# TM4C129ENCPDT register map
File version: 1.0
CPU: CORTEX_M4 1.0, other endian, MPU, FPU, 3 interrupt priority bits
Registers are 32-bit, read-write, reset 0x0 unless marked. A register's access mark holds for its fields unless they carry their own. Offsets are from the block's base; [hi:lo] are bit positions; lines under a group give offsets from that group; {n}, {i} and the like mark numbered series.

## NVIC — NVIC register addresses
Base 0xE000E000
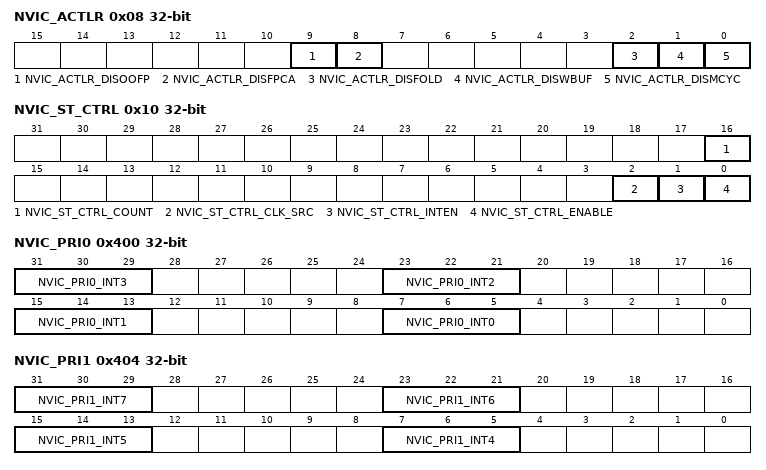
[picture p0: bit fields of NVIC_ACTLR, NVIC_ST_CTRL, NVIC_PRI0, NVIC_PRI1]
0x08 NVIC_ACTLR — Auxiliary Control
  [9] NVIC_ACTLR_DISOOFP — [9:9] Disable Out-Of-Order Floating Point
  [8] NVIC_ACTLR_DISFPCA — [8:8] Disable CONTROL
  [2] NVIC_ACTLR_DISFOLD — [2:2] Disable IT Folding
  [1] NVIC_ACTLR_DISWBUF — [1:1] Disable Write Buffer
  [0] NVIC_ACTLR_DISMCYC — [0:0] Disable Interrupts of Multiple Cycle Instructions
0x10 NVIC_ST_CTRL — SysTick Control and Status Register
  [16] NVIC_ST_CTRL_COUNT — [16:16] Count Flag
  [2] NVIC_ST_CTRL_CLK_SRC — [2:2] Clock Source
  [1] NVIC_ST_CTRL_INTEN — [1:1] Interrupt Enable
  [0] NVIC_ST_CTRL_ENABLE — [0:0] Enable
0x14 NVIC_ST_RELOAD — SysTick Reload Value Register
  [23:0] NVIC_ST_RELOAD — [23:0] Reload Value
0x18 NVIC_ST_CURRENT — SysTick Current Value Register
  [23:0] NVIC_ST_CURRENT — [23:0] Current Value
{0x100+4i} NVIC_EN{i} (i=0..3) — Interrupt {32i}-{32i+31} Set Enable
  [31:0] NVIC_EN{i}_INT — [31:0] Interrupt Enable
{0x180+4i} NVIC_DIS{i} (i=0..3) — Interrupt {32i}-{32i+31} Clear Enable
  [31:0] NVIC_DIS{i}_INT — [31:0] Interrupt Disable
{0x200+4i} NVIC_PEND{i} (i=0..3) — Interrupt {32i}-{32i+31} Set Pending
  [31:0] NVIC_PEND{i}_INT — [31:0] Interrupt Set Pending
{0x280+4i} NVIC_UNPEND{i} (i=0..3) — Interrupt {32i}-{32i+31} Clear Pending
  [31:0] NVIC_UNPEND{i}_INT — [31:0] Interrupt Clear Pending
{0x300+4i} NVIC_ACTIVE{i} (i=0..3) — Interrupt {32i}-{32i+31} Active Bit
  [31:0] NVIC_ACTIVE{i}_INT — [31:0] Interrupt Active
0x400 NVIC_PRI0 — Interrupt 0-3 Priority
  [8n+7:8n+5] NVIC_PRI0_INT{n} (n=0..3) — [{8n+7}:{8n+5}] Interrupt {n} Priority Mask
0x404 NVIC_PRI1 — Interrupt 4-7 Priority
  [8n-25:8n-27] NVIC_PRI1_INT{n} (n=4..7) — [{8n-25}:{8n-27}] Interrupt {n} Priority Mask
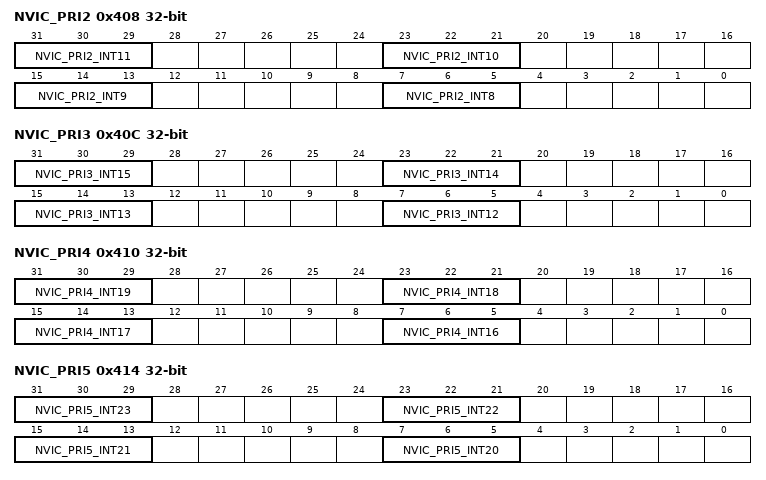
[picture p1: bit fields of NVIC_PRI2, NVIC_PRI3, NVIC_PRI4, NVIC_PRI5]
0x408 NVIC_PRI2 — Interrupt 8-11 Priority
  [8n-57:8n-59] NVIC_PRI2_INT{n} (n=8..11) — [{8n-57}:{8n-59}] Interrupt {n} Priority Mask
0x40C NVIC_PRI3 — Interrupt 12-15 Priority
  [8n-89:8n-91] NVIC_PRI3_INT{n} (n=12..15) — [{8n-89}:{8n-91}] Interrupt {n} Priority Mask
0x410 NVIC_PRI4 — Interrupt 16-19 Priority
  [8n-121:8n-123] NVIC_PRI4_INT{n} (n=16..19) — [{8n-121}:{8n-123}] Interrupt {n} Priority Mask
0x414 NVIC_PRI5 — Interrupt 20-23 Priority
  [8n-153:8n-155] NVIC_PRI5_INT{n} (n=20..23) — [{8n-153}:{8n-155}] Interrupt {n} Priority Mask
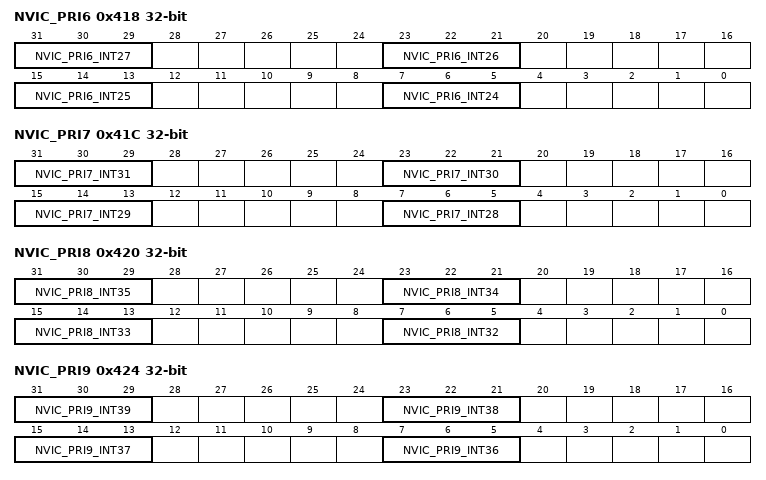
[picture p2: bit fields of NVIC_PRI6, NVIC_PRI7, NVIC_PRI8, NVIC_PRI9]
0x418 NVIC_PRI6 — Interrupt 24-27 Priority
  [8n-185:8n-187] NVIC_PRI6_INT{n} (n=24..27) — [{8n-185}:{8n-187}] Interrupt {n} Priority Mask
0x41C NVIC_PRI7 — Interrupt 28-31 Priority
  [8n-217:8n-219] NVIC_PRI7_INT{n} (n=28..31) — [{8n-217}:{8n-219}] Interrupt {n} Priority Mask
0x420 NVIC_PRI8 — Interrupt 32-35 Priority
  [8n-249:8n-251] NVIC_PRI8_INT{n} (n=32..35) — [{8n-249}:{8n-251}] Interrupt {n} Priority Mask
0x424 NVIC_PRI9 — Interrupt 36-39 Priority
  [8n-281:8n-283] NVIC_PRI9_INT{n} (n=36..39) — [{8n-281}:{8n-283}] Interrupt {n} Priority Mask
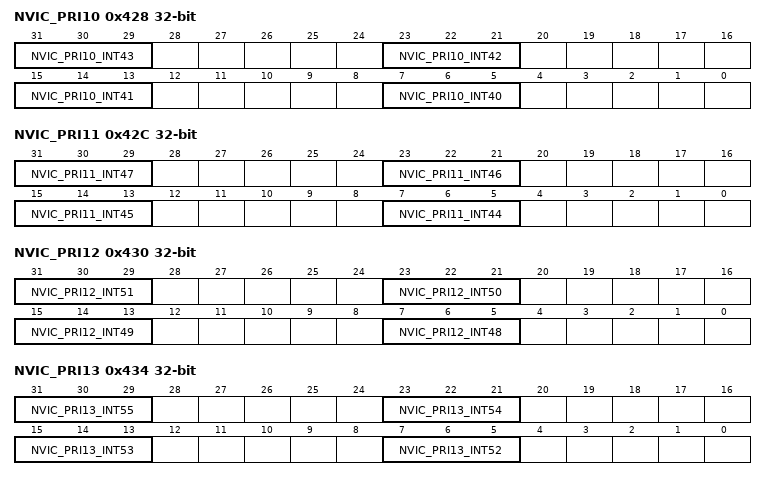
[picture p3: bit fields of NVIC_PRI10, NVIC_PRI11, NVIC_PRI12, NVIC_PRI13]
0x428 NVIC_PRI10 — Interrupt 40-43 Priority
  [8n-313:8n-315] NVIC_PRI10_INT{n} (n=40..43) — [{8n-313}:{8n-315}] Interrupt {n} Priority Mask
0x42C NVIC_PRI11 — Interrupt 44-47 Priority
  [8n-345:8n-347] NVIC_PRI11_INT{n} (n=44..47) — [{8n-345}:{8n-347}] Interrupt {n} Priority Mask
0x430 NVIC_PRI12 — Interrupt 48-51 Priority
  [8n-377:8n-379] NVIC_PRI12_INT{n} (n=48..51) — [{8n-377}:{8n-379}] Interrupt {n} Priority Mask
0x434 NVIC_PRI13 — Interrupt 52-55 Priority
  [8n-409:8n-411] NVIC_PRI13_INT{n} (n=52..55) — [{8n-409}:{8n-411}] Interrupt {n} Priority Mask
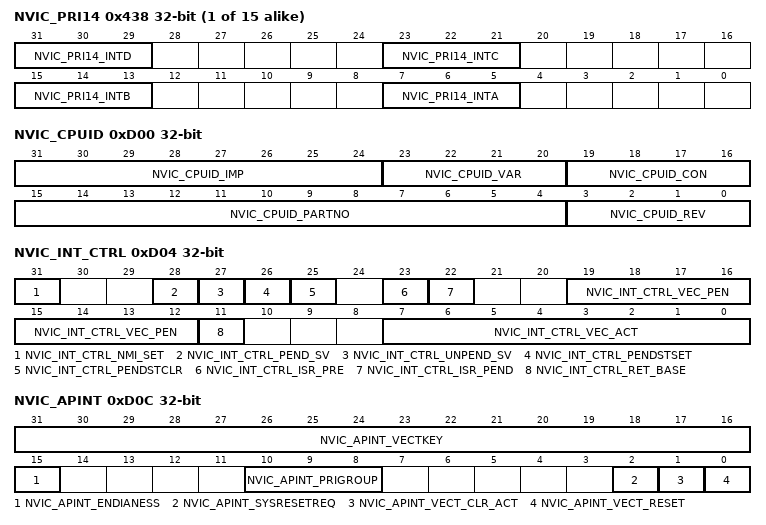
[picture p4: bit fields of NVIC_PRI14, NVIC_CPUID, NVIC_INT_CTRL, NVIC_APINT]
{0x400+4i} NVIC_PRI{i} (i=14..28) — Interrupt {4i}-{4i+3} Priority
  [31:29] NVIC_PRI{i}_INTD — [31:29] Interrupt {4i+3} Priority Mask
  [23:21] NVIC_PRI{i}_INTC — [23:21] Interrupt {4i+2} Priority Mask
  [15:13] NVIC_PRI{i}_INTB — [15:13] Interrupt {4i+1} Priority Mask
  [7:5] NVIC_PRI{i}_INTA — [7:5] Interrupt {4i} Priority Mask
0xD00 NVIC_CPUID — CPU ID Base
  [31:24] NVIC_CPUID_IMP — [31:24] Implementer Code
    0x41000000=NVIC_CPUID_IMP_ARM (ARM)
  [23:20] NVIC_CPUID_VAR — [23:20] Variant Number
  [19:16] NVIC_CPUID_CON — [19:16] Constant
  [15:4] NVIC_CPUID_PARTNO — [15:4] Part Number
    0xC240=NVIC_CPUID_PARTNO_CM4 (Cortex-M4 processor)
  [3:0] NVIC_CPUID_REV — [3:0] Revision Number
0xD04 NVIC_INT_CTRL — Interrupt Control and State
  [31] NVIC_INT_CTRL_NMI_SET — [31:31] NMI Set Pending
  [28] NVIC_INT_CTRL_PEND_SV — [28:28] PendSV Set Pending
  [27] NVIC_INT_CTRL_UNPEND_SV — [27:27] PendSV Clear Pending
  [26] NVIC_INT_CTRL_PENDSTSET — [26:26] SysTick Set Pending
  [25] NVIC_INT_CTRL_PENDSTCLR — [25:25] SysTick Clear Pending
  [23] NVIC_INT_CTRL_ISR_PRE — [23:23] Debug Interrupt Handling
  [22] NVIC_INT_CTRL_ISR_PEND — [22:22] Interrupt Pending
  [19:12] NVIC_INT_CTRL_VEC_PEN — [19:12] Interrupt Pending Vector Number
    0x2000=NVIC_INT_CTRL_VEC_PEN_NMI (NMI); 0x3000=NVIC_INT_CTRL_VEC_PEN_HARD (Hard fault); 0x4000=NVIC_INT_CTRL_VEC_PEN_MEM (Memory management fault); 0x5000=NVIC_INT_CTRL_VEC_PEN_BUS (Bus fault); 0x6000=NVIC_INT_CTRL_VEC_PEN_USG (Usage fault); 0xB000=NVIC_INT_CTRL_VEC_PEN_SVC (SVCall); 0xE000=NVIC_INT_CTRL_VEC_PEN_PNDSV (PendSV); 0xF000=NVIC_INT_CTRL_VEC_PEN_TICK (SysTick)
  [11] NVIC_INT_CTRL_RET_BASE — [11:11] Return to Base
  [7:0] NVIC_INT_CTRL_VEC_ACT — [7:0] Interrupt Pending Vector Number
0xD08 NVIC_VTABLE — Vector Table Offset
  [31:10] NVIC_VTABLE_OFFSET — [31:10] Vector Table Offset
0xD0C NVIC_APINT — Application Interrupt and Reset Control
  [31:16] NVIC_APINT_VECTKEY — [31:16] Register Key
    0x5FA0000=NVIC_APINT_VECTKEY (Vector key)
  [15] NVIC_APINT_ENDIANESS — [15:15] Data Endianess
  [10:8] NVIC_APINT_PRIGROUP — [10:8] Interrupt Priority Grouping
    0=NVIC_APINT_PRIGROUP_7_1 (Priority group 7.1 split); 0x100=NVIC_APINT_PRIGROUP_6_2 (Priority group 6.2 split); 0x200=NVIC_APINT_PRIGROUP_5_3 (Priority group 5.3 split); 0x300=NVIC_APINT_PRIGROUP_4_4 (Priority group 4.4 split); 0x400=NVIC_APINT_PRIGROUP_3_5 (Priority group 3.5 split); 0x500=NVIC_APINT_PRIGROUP_2_6 (Priority group 2.6 split); 0x600=NVIC_APINT_PRIGROUP_1_7 (Priority group 1.7 split); 0x700=NVIC_APINT_PRIGROUP_0_8 (Priority group 0.8 split)
  [2] NVIC_APINT_SYSRESETREQ — [2:2] System Reset Request
  [1] NVIC_APINT_VECT_CLR_ACT — [1:1] Clear Active NMI / Fault
  [0] NVIC_APINT_VECT_RESET — [0:0] System Reset
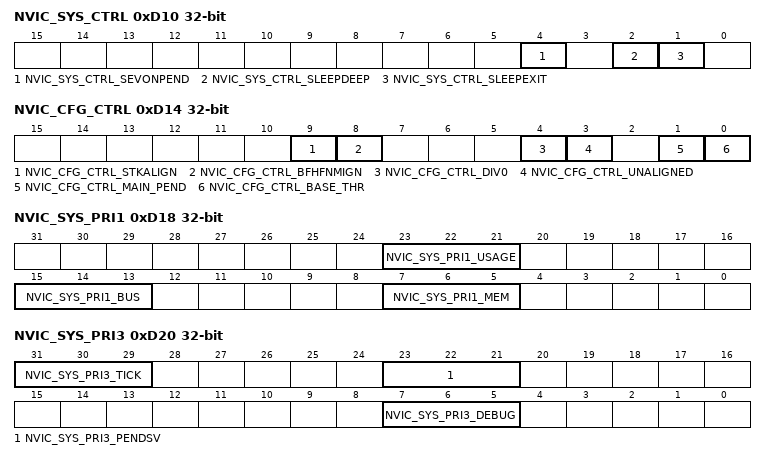
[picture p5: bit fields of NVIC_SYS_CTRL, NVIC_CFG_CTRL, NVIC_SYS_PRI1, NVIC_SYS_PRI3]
0xD10 NVIC_SYS_CTRL — System Control
  [4] NVIC_SYS_CTRL_SEVONPEND — [4:4] Wake Up on Pending
  [2] NVIC_SYS_CTRL_SLEEPDEEP — [2:2] Deep Sleep Enable
  [1] NVIC_SYS_CTRL_SLEEPEXIT — [1:1] Sleep on ISR Exit
0xD14 NVIC_CFG_CTRL — Configuration and Control
  [9] NVIC_CFG_CTRL_STKALIGN — [9:9] Stack Alignment on Exception Entry
  [8] NVIC_CFG_CTRL_BFHFNMIGN — [8:8] Ignore Bus Fault in NMI and Fault
  [4] NVIC_CFG_CTRL_DIV0 — [4:4] Trap on Divide by 0
  [3] NVIC_CFG_CTRL_UNALIGNED — [3:3] Trap on Unaligned Access
  [1] NVIC_CFG_CTRL_MAIN_PEND — [1:1] Allow Main Interrupt Trigger
  [0] NVIC_CFG_CTRL_BASE_THR — [0:0] Thread State Control
0xD18 NVIC_SYS_PRI1 — System Handler Priority 1
  [23:21] NVIC_SYS_PRI1_USAGE — [23:21] Usage Fault Priority
  [15:13] NVIC_SYS_PRI1_BUS — [15:13] Bus Fault Priority
  [7:5] NVIC_SYS_PRI1_MEM — [7:5] Memory Management Fault Priority
0xD1C NVIC_SYS_PRI2 — System Handler Priority 2
  [31:29] NVIC_SYS_PRI2_SVC — [31:29] SVCall Priority
0xD20 NVIC_SYS_PRI3 — System Handler Priority 3
  [31:29] NVIC_SYS_PRI3_TICK — [31:29] SysTick Exception Priority
  [23:21] NVIC_SYS_PRI3_PENDSV — [23:21] PendSV Priority
  [7:5] NVIC_SYS_PRI3_DEBUG — [7:5] Debug Priority
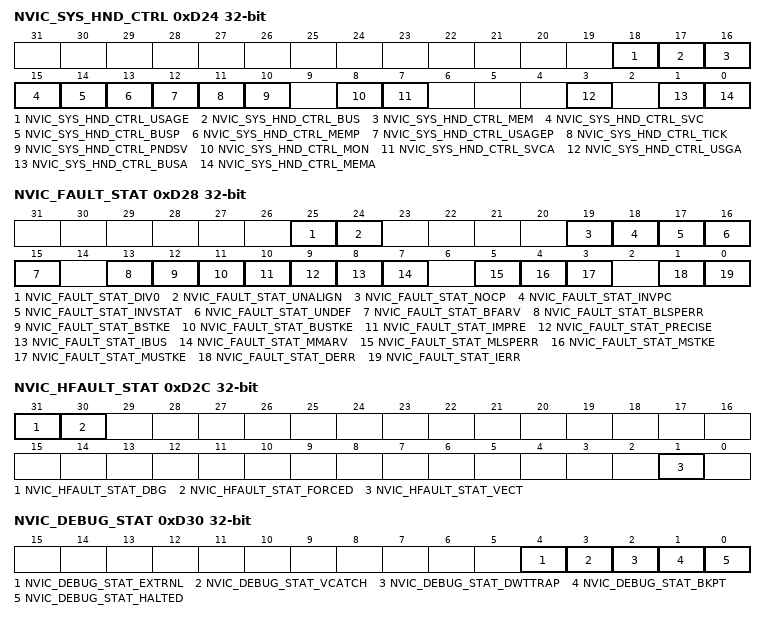
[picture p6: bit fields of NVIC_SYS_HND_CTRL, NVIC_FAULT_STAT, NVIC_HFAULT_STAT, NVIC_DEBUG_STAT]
0xD24 NVIC_SYS_HND_CTRL — System Handler Control and State
  [18] NVIC_SYS_HND_CTRL_USAGE — [18:18] Usage Fault Enable
  [17] NVIC_SYS_HND_CTRL_BUS — [17:17] Bus Fault Enable
  [16] NVIC_SYS_HND_CTRL_MEM — [16:16] Memory Management Fault Enable
  [15] NVIC_SYS_HND_CTRL_SVC — [15:15] SVC Call Pending
  [14] NVIC_SYS_HND_CTRL_BUSP — [14:14] Bus Fault Pending
  [13] NVIC_SYS_HND_CTRL_MEMP — [13:13] Memory Management Fault Pending
  [12] NVIC_SYS_HND_CTRL_USAGEP — [12:12] Usage Fault Pending
  [11] NVIC_SYS_HND_CTRL_TICK — [11:11] SysTick Exception Active
  [10] NVIC_SYS_HND_CTRL_PNDSV — [10:10] PendSV Exception Active
  [8] NVIC_SYS_HND_CTRL_MON — [8:8] Debug Monitor Active
  [7] NVIC_SYS_HND_CTRL_SVCA — [7:7] SVC Call Active
  [3] NVIC_SYS_HND_CTRL_USGA — [3:3] Usage Fault Active
  [1] NVIC_SYS_HND_CTRL_BUSA — [1:1] Bus Fault Active
  [0] NVIC_SYS_HND_CTRL_MEMA — [0:0] Memory Management Fault Active
0xD28 NVIC_FAULT_STAT — Configurable Fault Status
  [25] NVIC_FAULT_STAT_DIV0 — [25:25] Divide-by-Zero Usage Fault
  [24] NVIC_FAULT_STAT_UNALIGN — [24:24] Unaligned Access Usage Fault
  [19] NVIC_FAULT_STAT_NOCP — [19:19] No Coprocessor Usage Fault
  [18] NVIC_FAULT_STAT_INVPC — [18:18] Invalid PC Load Usage Fault
  [17] NVIC_FAULT_STAT_INVSTAT — [17:17] Invalid State Usage Fault
  [16] NVIC_FAULT_STAT_UNDEF — [16:16] Undefined Instruction Usage Fault
  [15] NVIC_FAULT_STAT_BFARV — [15:15] Bus Fault Address Register Valid
  [13] NVIC_FAULT_STAT_BLSPERR — [13:13] Bus Fault on Floating-Point Lazy State Preservation
  [12] NVIC_FAULT_STAT_BSTKE — [12:12] Stack Bus Fault
  [11] NVIC_FAULT_STAT_BUSTKE — [11:11] Unstack Bus Fault
  [10] NVIC_FAULT_STAT_IMPRE — [10:10] Imprecise Data Bus Error
  [9] NVIC_FAULT_STAT_PRECISE — [9:9] Precise Data Bus Error
  [8] NVIC_FAULT_STAT_IBUS — [8:8] Instruction Bus Error
  [7] NVIC_FAULT_STAT_MMARV — [7:7] Memory Management Fault Address Register Valid
  [5] NVIC_FAULT_STAT_MLSPERR — [5:5] Memory Management Fault on Floating-Point Lazy State Preservation
  [4] NVIC_FAULT_STAT_MSTKE — [4:4] Stack Access Violation
  [3] NVIC_FAULT_STAT_MUSTKE — [3:3] Unstack Access Violation
  [1] NVIC_FAULT_STAT_DERR — [1:1] Data Access Violation
  [0] NVIC_FAULT_STAT_IERR — [0:0] Instruction Access Violation
0xD2C NVIC_HFAULT_STAT — Hard Fault Status
  [31] NVIC_HFAULT_STAT_DBG — [31:31] Debug Event
  [30] NVIC_HFAULT_STAT_FORCED — [30:30] Forced Hard Fault
  [1] NVIC_HFAULT_STAT_VECT — [1:1] Vector Table Read Fault
0xD30 NVIC_DEBUG_STAT — Debug Status Register
  [4] NVIC_DEBUG_STAT_EXTRNL — [4:4] EDBGRQ asserted
  [3] NVIC_DEBUG_STAT_VCATCH — [3:3] Vector catch
  [2] NVIC_DEBUG_STAT_DWTTRAP — [2:2] DWT match
  [1] NVIC_DEBUG_STAT_BKPT — [1:1] Breakpoint instruction
  [0] NVIC_DEBUG_STAT_HALTED — [0:0] Halt request
0xD34 NVIC_MM_ADDR — Memory Management Fault Address
  [31:0] NVIC_MM_ADDR — [31:0] Fault Address
0xD38 NVIC_FAULT_ADDR — Bus Fault Address
  [31:0] NVIC_FAULT_ADDR — [31:0] Fault Address
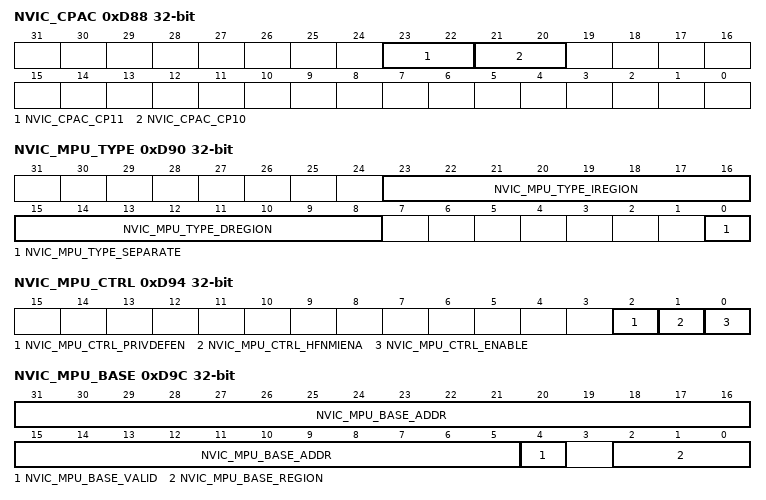
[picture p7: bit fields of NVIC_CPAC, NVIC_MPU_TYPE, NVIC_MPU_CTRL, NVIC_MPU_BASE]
0xD88 NVIC_CPAC — Coprocessor Access Control
  [23:22] NVIC_CPAC_CP11 — [23:22] CP11 Coprocessor Access Privilege
    0=NVIC_CPAC_CP11_DIS (Access Denied); 0x400000=NVIC_CPAC_CP11_PRIV (Privileged Access Only); 0xC00000=NVIC_CPAC_CP11_FULL (Full Access)
  [21:20] NVIC_CPAC_CP10 — [21:20] CP10 Coprocessor Access Privilege
    0=NVIC_CPAC_CP10_DIS (Access Denied); 0x100000=NVIC_CPAC_CP10_PRIV (Privileged Access Only); 0x300000=NVIC_CPAC_CP10_FULL (Full Access)
0xD90 NVIC_MPU_TYPE — MPU Type
  [23:16] NVIC_MPU_TYPE_IREGION — [23:16] Number of I Regions
  [15:8] NVIC_MPU_TYPE_DREGION — [15:8] Number of D Regions
  [0] NVIC_MPU_TYPE_SEPARATE — [0:0] Separate or Unified MPU
0xD94 NVIC_MPU_CTRL — MPU Control
  [2] NVIC_MPU_CTRL_PRIVDEFEN — [2:2] MPU Default Region
  [1] NVIC_MPU_CTRL_HFNMIENA — [1:1] MPU Enabled During Faults
  [0] NVIC_MPU_CTRL_ENABLE — [0:0] MPU Enable
0xD98 NVIC_MPU_NUMBER — MPU Region Number
  [2:0] NVIC_MPU_NUMBER — [2:0] MPU Region to Access
0xD9C NVIC_MPU_BASE — MPU Region Base Address
  [31:5] NVIC_MPU_BASE_ADDR — [31:5] Base Address Mask
  [4] NVIC_MPU_BASE_VALID — [4:4] Region Number Valid
  [2:0] NVIC_MPU_BASE_REGION — [2:0] Region Number
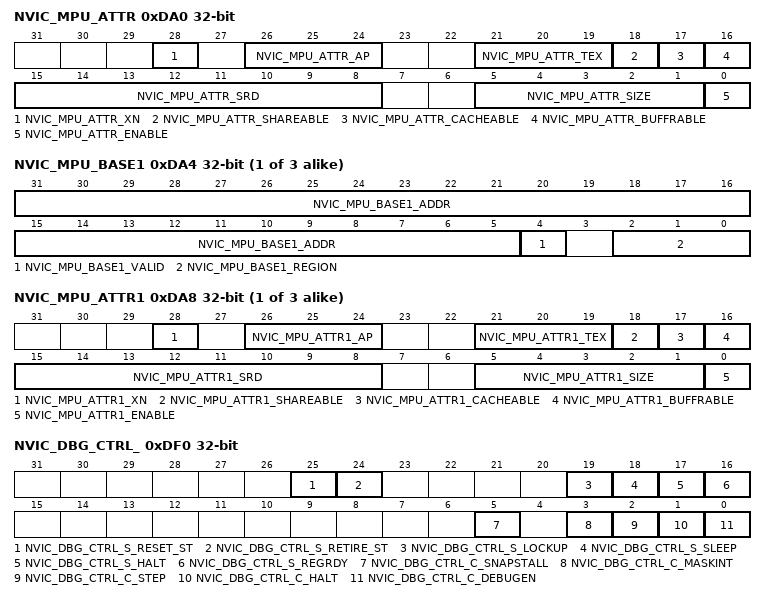
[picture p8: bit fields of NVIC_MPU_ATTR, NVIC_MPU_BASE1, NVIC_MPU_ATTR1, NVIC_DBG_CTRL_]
0xDA0 NVIC_MPU_ATTR — MPU Region Attribute and Size
  [28] NVIC_MPU_ATTR_XN — [28:28] Instruction Access Disable
  [26:24] NVIC_MPU_ATTR_AP — [26:24] Access Privilege
  [21:19] NVIC_MPU_ATTR_TEX — [21:19] Type Extension Mask
  [18] NVIC_MPU_ATTR_SHAREABLE — [18:18] Shareable
  [17] NVIC_MPU_ATTR_CACHEABLE — [17:17] Cacheable
  [16] NVIC_MPU_ATTR_BUFFRABLE — [16:16] Bufferable
  [15:8] NVIC_MPU_ATTR_SRD — [15:8] Subregion Disable Bits
  [5:1] NVIC_MPU_ATTR_SIZE — [5:1] Region Size Mask
  [0] NVIC_MPU_ATTR_ENABLE — [0:0] Region Enable
{0xD9C+8i} NVIC_MPU_BASE{i} (i=1..3) — MPU Region Base Address Alias {i}
  [31:5] NVIC_MPU_BASE{i}_ADDR — [31:5] Base Address Mask
  [4] NVIC_MPU_BASE{i}_VALID — [4:4] Region Number Valid
  [2:0] NVIC_MPU_BASE{i}_REGION — [2:0] Region Number
{0xDA0+8i} NVIC_MPU_ATTR{i} (i=1..3) — MPU Region Attribute and Size Alias {i}
  [28] NVIC_MPU_ATTR{i}_XN — [28:28] Instruction Access Disable
  [26:24] NVIC_MPU_ATTR{i}_AP — [26:24] Access Privilege
  [21:19] NVIC_MPU_ATTR{i}_TEX — [21:19] Type Extension Mask
  [18] NVIC_MPU_ATTR{i}_SHAREABLE — [18:18] Shareable
  [17] NVIC_MPU_ATTR{i}_CACHEABLE — [17:17] Cacheable
  [16] NVIC_MPU_ATTR{i}_BUFFRABLE — [16:16] Bufferable
  [15:8] NVIC_MPU_ATTR{i}_SRD — [15:8] Subregion Disable Bits
  [5:1] NVIC_MPU_ATTR{i}_SIZE — [5:1] Region Size Mask
  [0] NVIC_MPU_ATTR{i}_ENABLE — [0:0] Region Enable
0xDF0 NVIC_DBG_CTRL — Debug Control and Status Reg
  [31:16] NVIC_DBG_CTRL_DBGKEY — [31:16] Debug key mask
    0xA05F0000=NVIC_DBG_CTRL_DBGKEY (Debug key)
0xDF0 NVIC_DBG_CTRL_ — Debug Control and Status Reg
  [25] NVIC_DBG_CTRL_S_RESET_ST — [25:25] Core has reset since last read
  [24] NVIC_DBG_CTRL_S_RETIRE_ST — [24:24] Core has executed insruction since last read
  [19] NVIC_DBG_CTRL_S_LOCKUP — [19:19] Core is locked up
  [18] NVIC_DBG_CTRL_S_SLEEP — [18:18] Core is sleeping
  [17] NVIC_DBG_CTRL_S_HALT — [17:17] Core status on halt
  [16] NVIC_DBG_CTRL_S_REGRDY — [16:16] Register read/write available
  [5] NVIC_DBG_CTRL_C_SNAPSTALL — [5:5] Breaks a stalled load/store
  [3] NVIC_DBG_CTRL_C_MASKINT — [3:3] Mask interrupts when stepping
  [2] NVIC_DBG_CTRL_C_STEP — [2:2] Step the core
  [1] NVIC_DBG_CTRL_C_HALT — [1:1] Halt the core
  [0] NVIC_DBG_CTRL_C_DEBUGEN — [0:0] Enable debug
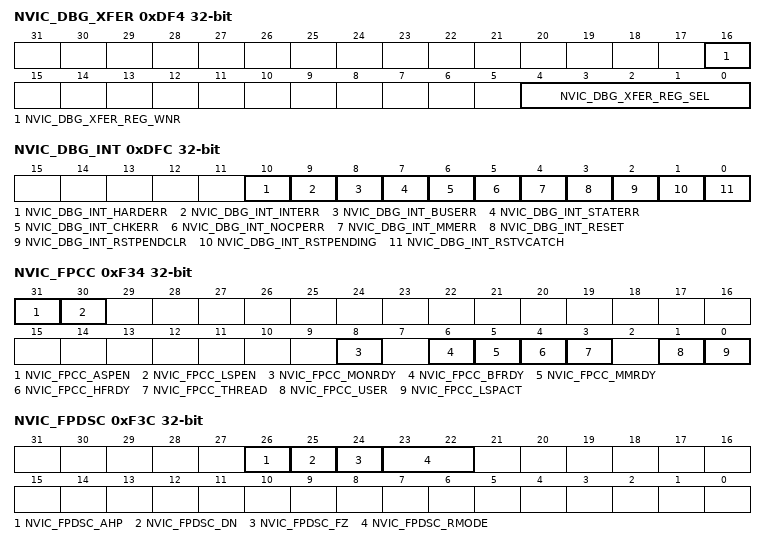
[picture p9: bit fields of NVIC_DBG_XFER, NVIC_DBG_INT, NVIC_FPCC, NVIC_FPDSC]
0xDF4 NVIC_DBG_XFER — Debug Core Reg. Transfer Select
  [16] NVIC_DBG_XFER_REG_WNR — [16:16] Write or not read
  [4:0] NVIC_DBG_XFER_REG_SEL — [4:0] Register
    {v}=NVIC_DBG_XFER_REG_R{v} (Register R{v}) (v=0..15); 16=NVIC_DBG_XFER_REG_FLAGS (xPSR/Flags register); 17=NVIC_DBG_XFER_REG_MSP (Main SP); 18=NVIC_DBG_XFER_REG_PSP (Process SP); 19=NVIC_DBG_XFER_REG_DSP (Deep SP); 20=NVIC_DBG_XFER_REG_CFBP (Control/Fault/BasePri/PriMask)
0xDF8 NVIC_DBG_DATA — Debug Core Register Data
  [31:0] NVIC_DBG_DATA — [31:0] Data temporary cache
0xDFC NVIC_DBG_INT — Debug Reset Interrupt Control
  [10] NVIC_DBG_INT_HARDERR — [10:10] Debug trap on hard fault
  [9] NVIC_DBG_INT_INTERR — [9:9] Debug trap on interrupt errors
  [8] NVIC_DBG_INT_BUSERR — [8:8] Debug trap on bus error
  [7] NVIC_DBG_INT_STATERR — [7:7] Debug trap on usage fault state
  [6] NVIC_DBG_INT_CHKERR — [6:6] Debug trap on usage fault check
  [5] NVIC_DBG_INT_NOCPERR — [5:5] Debug trap on coprocessor error
  [4] NVIC_DBG_INT_MMERR — [4:4] Debug trap on mem manage fault
  [3] NVIC_DBG_INT_RESET — [3:3] Core reset status
  [2] NVIC_DBG_INT_RSTPENDCLR — [2:2] Clear pending core reset
  [1] NVIC_DBG_INT_RSTPENDING — [1:1] Core reset is pending
  [0] NVIC_DBG_INT_RSTVCATCH — [0:0] Reset vector catch
0xF00 NVIC_SW_TRIG — Software Trigger Interrupt
  [7:0] NVIC_SW_TRIG_INTID — [7:0] Interrupt ID
0xF34 NVIC_FPCC — Floating-Point Context Control
  [31] NVIC_FPCC_ASPEN — [31:31] Automatic State Preservation Enable
  [30] NVIC_FPCC_LSPEN — [30:30] Lazy State Preservation Enable
  [8] NVIC_FPCC_MONRDY — [8:8] Monitor Ready
  [6] NVIC_FPCC_BFRDY — [6:6] Bus Fault Ready
  [5] NVIC_FPCC_MMRDY — [5:5] Memory Management Fault Ready
  [4] NVIC_FPCC_HFRDY — [4:4] Hard Fault Ready
  [3] NVIC_FPCC_THREAD — [3:3] Thread Mode
  [1] NVIC_FPCC_USER — [1:1] User Privilege Level
  [0] NVIC_FPCC_LSPACT — [0:0] Lazy State Preservation Active
0xF38 NVIC_FPCA — Floating-Point Context Address
  [31:3] NVIC_FPCA_ADDRESS — [31:3] Address
0xF3C NVIC_FPDSC — Floating-Point Default Status Control
  [26] NVIC_FPDSC_AHP — [26:26] AHP Bit Default
  [25] NVIC_FPDSC_DN — [25:25] DN Bit Default
  [24] NVIC_FPDSC_FZ — [24:24] FZ Bit Default
  [23:22] NVIC_FPDSC_RMODE — [23:22] RMODE Bit Default
    0=NVIC_FPDSC_RMODE_RN (Round to Nearest (RN) mode); 0x400000=NVIC_FPDSC_RMODE_RP (Round towards Plus Infinity (RP) mode); 0x800000=NVIC_FPDSC_RMODE_RM (Round towards Minus Infinity (RM) mode); 0xC00000=NVIC_FPDSC_RMODE_RZ (Round towards Zero (RZ) mode)
